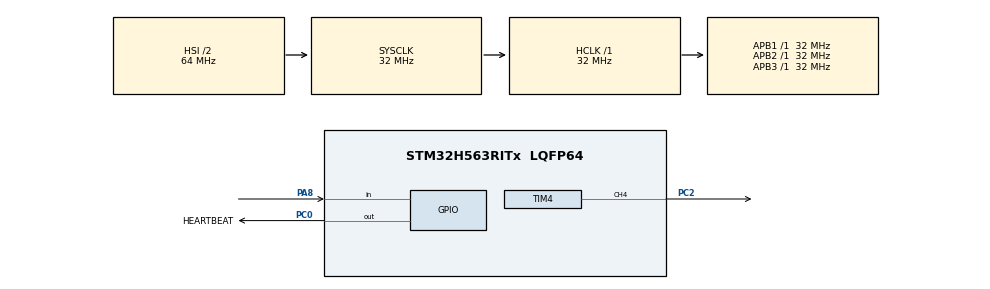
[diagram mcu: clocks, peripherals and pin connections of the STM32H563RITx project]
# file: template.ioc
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BOOTPATH.BootPathName=LEGACY
BOOTPATH.UserSelectedBootPath=LEGACY
CORTEX_M33_NS.Number-Cortex_Memory_Protection_Unit_Region0_OTP_RO_AREAS_Settings=MPU_REGION_NUMBER0
CORTEX_M33_NS.default_mode_Activation=1
CORTEX_M33_NS.userName=CORTEX_M33
Mcu.Family=STM32H5
Mcu.Name=STM32H563RITx
Mcu.Package=LQFP64
NVIC.PriorityGroup=NVIC_PRIORITYGROUP_4
PA13(JTMS/SWDIO).Mode=Trace_Asynchronous_SW
PA13(JTMS/SWDIO).Signal=DEBUG_JTMS-SWDIO
PA14(JTCK/SWCLK).Mode=Trace_Asynchronous_SW
PA14(JTCK/SWCLK).Signal=DEBUG_JTCK-SWCLK
PA8.GPIO_PuPd=GPIO_PULLUP
PA8.Signal=GPIO_Input
PB3(JTDO/TRACESWO).Mode=Trace_Asynchronous_SW
PB3(JTDO/TRACESWO).Signal=DEBUG_JTDO-SWO
PC0.GPIO_Label=HEARTBEAT
PC0.Signal=GPIO_Output
PC2.Signal=S_TIM4_CH4
ProjectManager.HeapSize=0x200
ProjectManager.StackSize=0x400
ProjectManager.TargetToolchain=STM32CubeIDE
RCC.ADCFreq_Value=32000000
RCC.AHBFreq_Value=32000000
RCC.APB1Freq_Value=32000000
RCC.APB1TimFreq_Value=32000000
RCC.APB2Freq_Value=32000000
RCC.APB2TimFreq_Value=32000000
RCC.APB3Freq_Value=32000000
RCC.CSI_VALUE=4000000
RCC.CortexFreq_Value=32000000
RCC.EPOD_VALUE=4000000
RCC.FDCANClockSelection=RCC_FDCANCLKSOURCE_PLL2Q
RCC.HCLKFreq_Value=32000000
RCC.HSE_VALUE=25000000
RCC.HSI48_VALUE=48000000
RCC.HSI_VALUE=64000000
RCC.LSE_VALUE=32768
RCC.LSIRC_VALUE=32000
RCC.PLL1Q=4
RCC.PLL2FRACN=0
RCC.PLL2N=32
RCC.PLL2Q=4
RCC.PLLFRACN=0
RCC.PLLN=32
RCC.SYSCLKFreq_VALUE=32000000
RCC.USBFreq_Value=48000000
RCC.VCOOutputFreq_Value=128000000
SH.S_TIM4_CH4.0=TIM4_CH4,PWM Generation4 CH4
TIM4.Channel-PWM\ Generation4\ CH4=TIM_CHANNEL_4
VP_BOOTPATH_VS_BOOTPATH.Mode=BP_Activate
VP_CORTEX_M33_NS_VS_Hclk.Mode=Hclk_Mode
VP_ICACHE_VS_ICACHE.Mode=DirectMappedCache
VP_MEMORYMAP_VS_MEMORYMAP.Mode=CurAppReg
VP_PWR_VS_LPOM.Mode=PowerOptimisation
VP_PWR_VS_SECSignals.Mode=Security/Privilege
VP_TIM4_VS_ClockSourceINT.Mode=Internal
board=custom

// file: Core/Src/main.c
/* USER CODE BEGIN Header */
/**
  ******************************************************************************
  * @file           : main.c
  * @brief          : Main program body
  ******************************************************************************
  * @attention
  *
  * Copyright (c) 2026 STMicroelectronics.
  * All rights reserved.
  *
  * This software is licensed under terms that can be found in the LICENSE file
  * in the root directory of this software component.
  * If no LICENSE file comes with this software, it is provided AS-IS.
  *
  ******************************************************************************
  */
/* USER CODE END Header */
#include "main.h"

TIM_HandleTypeDef htim4;

void SystemClock_Config(void);
static void MPU_Config(void);
static void MX_GPIO_Init(void);
static void MX_ICACHE_Init(void);
static void MX_TIM4_Init(void);

int main(void)
{

  /* MCU Configuration--------------------------------------------------------*/

  /* MPU Configuration--------------------------------------------------------*/
  MPU_Config();

  /* Reset of all peripherals, Initializes the Flash interface and the Systick. */
  HAL_Init();

  /* Configure the system clock */
  SystemClock_Config();

  /* Initialize all configured peripherals */
  MX_GPIO_Init();
  MX_ICACHE_Init();
  MX_TIM4_Init();

  /* Infinite loop */
  /* USER CODE BEGIN WHILE */
  HAL_TIM_PWM_Start(&htim4, TIM_CHANNEL_4);

  uint32_t run_count = 0;
  while (1)
  {
    /* USER CODE END WHILE */

    /* USER CODE BEGIN 3 */
	if (HAL_GPIO_ReadPin(GPIOA, GPIO_PIN_8) == 0) {
		HAL_GPIO_WritePin(HEARTBEAT_GPIO_Port, HEARTBEAT_Pin,1);
	}
	else {
		HAL_GPIO_WritePin(HEARTBEAT_GPIO_Port, HEARTBEAT_Pin,1);
	}
	uint16_t ccr_value = ((run_count % 100) * 65535) / 100;
	__HAL_TIM_SET_COMPARE(&htim4, TIM_CHANNEL_4, ccr_value);
	run_count++;
	HAL_Delay(1000); //delay

  }
  /* USER CODE END 3 */
}

void SystemClock_Config(void)
{
  RCC_OscInitTypeDef RCC_OscInitStruct = {0};
  RCC_ClkInitTypeDef RCC_ClkInitStruct = {0};

  /** Configure the main internal regulator output voltage
  */
  __HAL_PWR_VOLTAGESCALING_CONFIG(PWR_REGULATOR_VOLTAGE_SCALE3);

  while(!__HAL_PWR_GET_FLAG(PWR_FLAG_VOSRDY)) {}

  /** Initializes the RCC Oscillators according to the specified parameters
  * in the RCC_OscInitTypeDef structure.
  */
  RCC_OscInitStruct.OscillatorType = RCC_OSCILLATORTYPE_HSI;
  RCC_OscInitStruct.HSIState = RCC_HSI_ON;
  RCC_OscInitStruct.HSIDiv = RCC_HSI_DIV2;
  RCC_OscInitStruct.HSICalibrationValue = RCC_HSICALIBRATION_DEFAULT;
  RCC_OscInitStruct.PLL.PLLState = RCC_PLL_NONE;
  if (HAL_RCC_OscConfig(&RCC_OscInitStruct) != HAL_OK)
  {
    Error_Handler();
  }

  /** Initializes the CPU, AHB and APB buses clocks
  */
  RCC_ClkInitStruct.ClockType = RCC_CLOCKTYPE_HCLK|RCC_CLOCKTYPE_SYSCLK
                              |RCC_CLOCKTYPE_PCLK1|RCC_CLOCKTYPE_PCLK2
                              |RCC_CLOCKTYPE_PCLK3;
  RCC_ClkInitStruct.SYSCLKSource = RCC_SYSCLKSOURCE_HSI;
  RCC_ClkInitStruct.AHBCLKDivider = RCC_SYSCLK_DIV1;
  RCC_ClkInitStruct.APB1CLKDivider = RCC_HCLK_DIV1;
  RCC_ClkInitStruct.APB2CLKDivider = RCC_HCLK_DIV1;
  RCC_ClkInitStruct.APB3CLKDivider = RCC_HCLK_DIV1;

  if (HAL_RCC_ClockConfig(&RCC_ClkInitStruct, FLASH_LATENCY_1) != HAL_OK)
  {
    Error_Handler();
  }

  /** Configure the programming delay
  */
  __HAL_FLASH_SET_PROGRAM_DELAY(FLASH_PROGRAMMING_DELAY_0);
}

static void MX_ICACHE_Init(void)
{

  /** Enable instruction cache in 1-way (direct mapped cache)
  */
  if (HAL_ICACHE_ConfigAssociativityMode(ICACHE_1WAY) != HAL_OK)
  {
    Error_Handler();
  }
  if (HAL_ICACHE_Enable() != HAL_OK)
  {
    Error_Handler();
  }

}

static void MX_TIM4_Init(void)
{

  TIM_ClockConfigTypeDef sClockSourceConfig = {0};
  TIM_MasterConfigTypeDef sMasterConfig = {0};
  TIM_OC_InitTypeDef sConfigOC = {0};

  htim4.Instance = TIM4;
  htim4.Init.Prescaler = 0;
  htim4.Init.CounterMode = TIM_COUNTERMODE_UP;
  htim4.Init.Period = 65535;
  htim4.Init.ClockDivision = TIM_CLOCKDIVISION_DIV1;
  htim4.Init.AutoReloadPreload = TIM_AUTORELOAD_PRELOAD_DISABLE;
  if (HAL_TIM_Base_Init(&htim4) != HAL_OK)
  {
    Error_Handler();
  }
  sClockSourceConfig.ClockSource = TIM_CLOCKSOURCE_INTERNAL;
  if (HAL_TIM_ConfigClockSource(&htim4, &sClockSourceConfig) != HAL_OK)
  {
    Error_Handler();
  }
  if (HAL_TIM_PWM_Init(&htim4) != HAL_OK)
  {
    Error_Handler();
  }
  sMasterConfig.MasterOutputTrigger = TIM_TRGO_RESET;
  sMasterConfig.MasterSlaveMode = TIM_MASTERSLAVEMODE_DISABLE;
  if (HAL_TIMEx_MasterConfigSynchronization(&htim4, &sMasterConfig) != HAL_OK)
  {
    Error_Handler();
  }
  sConfigOC.OCMode = TIM_OCMODE_PWM1;
  sConfigOC.Pulse = 0;
  sConfigOC.OCPolarity = TIM_OCPOLARITY_HIGH;
  sConfigOC.OCFastMode = TIM_OCFAST_DISABLE;
  if (HAL_TIM_PWM_ConfigChannel(&htim4, &sConfigOC, TIM_CHANNEL_4) != HAL_OK)
  {
    Error_Handler();
  }
  HAL_TIM_MspPostInit(&htim4);

}

static void MX_GPIO_Init(void)
{
  GPIO_InitTypeDef GPIO_InitStruct = {0};

  /* GPIO Ports Clock Enable */
  __HAL_RCC_GPIOC_CLK_ENABLE();
  __HAL_RCC_GPIOA_CLK_ENABLE();
  __HAL_RCC_GPIOB_CLK_ENABLE();

  /*Configure GPIO pin Output Level */
  HAL_GPIO_WritePin(HEARTBEAT_GPIO_Port, HEARTBEAT_Pin, GPIO_PIN_RESET);

  /*Configure GPIO pin : HEARTBEAT_Pin */
  GPIO_InitStruct.Pin = HEARTBEAT_Pin;
  GPIO_InitStruct.Mode = GPIO_MODE_OUTPUT_PP;
  GPIO_InitStruct.Pull = GPIO_PULLUP;
  GPIO_InitStruct.Speed = GPIO_SPEED_FREQ_LOW;
  HAL_GPIO_Init(HEARTBEAT_GPIO_Port, &GPIO_InitStruct);

  /*Configure GPIO pin : PA8 */
  GPIO_InitStruct.Pin = GPIO_PIN_8;
  GPIO_InitStruct.Mode = GPIO_MODE_INPUT;
  GPIO_InitStruct.Pull = GPIO_PULLUP;
  HAL_GPIO_Init(GPIOA, &GPIO_InitStruct);

}

 /* MPU Configuration */

void MPU_Config(void)
{
  MPU_Region_InitTypeDef MPU_InitStruct = {0};
  MPU_Attributes_InitTypeDef MPU_AttributesInit = {0};

  /* Disables the MPU */
  HAL_MPU_Disable();

  /** Initializes and configures the Region 0 and the memory to be protected
  */
  MPU_InitStruct.Enable = MPU_REGION_ENABLE;
  MPU_InitStruct.Number = MPU_REGION_NUMBER0;
  MPU_InitStruct.BaseAddress = 0x08FFF000;
  MPU_InitStruct.LimitAddress = 0x08FFFFFF;
  MPU_InitStruct.AttributesIndex = MPU_ATTRIBUTES_NUMBER0;
  MPU_InitStruct.AccessPermission = MPU_REGION_ALL_RO;
  MPU_InitStruct.DisableExec = MPU_INSTRUCTION_ACCESS_DISABLE;
  MPU_InitStruct.IsShareable = MPU_ACCESS_NOT_SHAREABLE;

  HAL_MPU_ConfigRegion(&MPU_InitStruct);

  /** Initializes and configures the Attribute 0 and the memory to be protected
  */
  MPU_AttributesInit.Number = MPU_ATTRIBUTES_NUMBER0;
  MPU_AttributesInit.Attributes = INNER_OUTER(MPU_NOT_CACHEABLE);

  HAL_MPU_ConfigMemoryAttributes(&MPU_AttributesInit);
  /* Enables the MPU */
  HAL_MPU_Enable(MPU_PRIVILEGED_DEFAULT);

}

void Error_Handler(void)
{
  __disable_irq();
  while (1)
  {
  }
}
